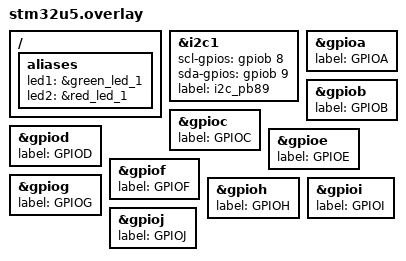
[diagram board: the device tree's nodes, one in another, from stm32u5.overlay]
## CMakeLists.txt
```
# SPDX-License-Identifier: Apache-2.0

cmake_minimum_required(VERSION 3.20.0)

set(DTC_OVERLAY_FILE stm32u5.overlay)
find_package(Zephyr REQUIRED HINTS $ENV{ZEPHYR_BASE})
project(shell_module)

target_sources(app PRIVATE src/main.c src/test_module.c src/misc_cmd.c)
target_sources_ifdef(CONFIG_SHELL_DYNAMIC_CMDS app PRIVATE src/dynamic_cmd.c)
target_sources_ifdef(CONFIG_SHELL_BACKEND_SERIAL app PRIVATE src/uart_reinit.c)
target_sources_ifdef(CONFIG_SHELL_START_OBSCURED app PRIVATE src/login_cmd.c)
```

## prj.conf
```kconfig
CONFIG_PRINTK=y
CONFIG_SHELL=y
CONFIG_LOG=y
CONFIG_LOG_CMDS=y
CONFIG_INIT_STACKS=y
CONFIG_THREAD_STACK_INFO=y
CONFIG_KERNEL_SHELL=y
CONFIG_THREAD_MONITOR=y
CONFIG_BOOT_BANNER=n
CONFIG_THREAD_NAME=y
CONFIG_DEVICE_SHELL=y
CONFIG_POSIX_API=y
CONFIG_POSIX_TIMERS=y
CONFIG_DATE_SHELL=y
CONFIG_THREAD_RUNTIME_STATS=y
CONFIG_THREAD_RUNTIME_STATS_USE_TIMING_FUNCTIONS=y
CONFIG_STATS=y
CONFIG_STATS_SHELL=y
CONFIG_GPIO=y
CONFIG_GPIO_SHELL=y
CONFIG_SHELL_DYNAMIC_CMDS=y
CONFIG_I2C=y
CONFIG_I2C_SHELL=y
CONFIG_FLASH=y
CONFIG_FLASH_SHELL=y
```

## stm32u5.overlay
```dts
/ {
	aliases {
		led1 = &green_led_1;
        led2 = &red_led_1;
	};
};

&i2c1 {
    status = "okay";
    scl-gpios = <&gpiob 8 GPIO_OPEN_DRAIN>; 
    sda-gpios = <&gpiob 9 GPIO_OPEN_DRAIN>; 
    label = "i2c_pb89";
};

&gpioa {
    label = "GPIOA";
};

&gpiob {
    label = "GPIOB";
};

&gpioc {
    label = "GPIOC";
};

&gpiod {
    label = "GPIOD";
};

&gpioe {
    label = "GPIOE";
};

&gpiof {
    label = "GPIOF";
};

&gpiog {
    label = "GPIOG";
};

&gpioh {
    label = "GPIOH";
};

&gpioi {
    label = "GPIOI";
};

&gpioj {
    label = "GPIOJ";
};
```

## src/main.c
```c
/*
 * Copyright (c) 2015 Intel Corporation
 *
 * SPDX-License-Identifier: Apache-2.0
 */

#include <zephyr/kernel.h>
#include <zephyr/shell/shell.h>
#include <zephyr/version.h>
#include <zephyr/logging/log.h>
#include <stdlib.h>
#include <zephyr/device.h>
#include <zephyr/drivers/uart.h>
#include <zephyr/usb/usb_device.h>
#include <zephyr/drivers/gpio.h>
#include <ctype.h>

#ifdef CONFIG_ARCH_POSIX
#include <unistd.h>
#else
#include <zephyr/posix/unistd.h>
#endif

/* The devicetree node identifier for the "led0" alias. */
#define LED0_NODE DT_ALIAS(led0)
#define LED1_NODE DT_ALIAS(led1)
#define LED2_NODE DT_ALIAS(led2)

LOG_MODULE_REGISTER(app);

struct led {
	struct gpio_dt_spec spec;
	uint8_t num;
};

static const struct led led0 = {
	.spec = GPIO_DT_SPEC_GET_OR(LED0_NODE, gpios, {0}),
	.num = 0,
};

static const struct led led1 = {
	.spec = GPIO_DT_SPEC_GET_OR(LED1_NODE, gpios, {0}),
	.num = 1,
};

void blink(const struct led *led, uint32_t sleep_ms, uint32_t id)
{
	const struct gpio_dt_spec *spec = &led->spec;
	int cnt = 0;
	int ret;

	if (!device_is_ready(spec->port)) {
		LOG_ERR("Error: %s device is not ready\n", spec->port->name);
		return;
	}

	ret = gpio_pin_configure_dt(spec, GPIO_OUTPUT);
	if (ret != 0) {
		LOG_ERR("Error %d: failed to configure pin %d (LED '%d')\n", ret, spec->pin,
			led->num);
		return;
	}

	while (1) {
		gpio_pin_set(spec->port, spec->pin, cnt % 2);

		k_msleep(sleep_ms);
		cnt++;
	}
}

void blink0_thread(void)
{
	blink(&led0, 1000, 0);
}

void blink1_thread(void)
{
	blink(&led1, 5000, 1);
}

#define LED_PRIORITY (6)
K_THREAD_DEFINE(blink0_id, 1024, blink0_thread, NULL, NULL, NULL, LED_PRIORITY, 0, 0);
K_THREAD_DEFINE(blink1_id, 1024, blink1_thread, NULL, NULL, NULL, LED_PRIORITY, 0, 0);
```

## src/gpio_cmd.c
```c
#include <zephyr/kernel.h>
#include <zephyr/shell/shell.h>
#include <zephyr/version.h>
#include <zephyr/logging/log.h>
#include <stdlib.h>
#include <zephyr/device.h>
#include <zephyr/drivers/uart.h>
#include <zephyr/usb/usb_device.h>
#include <zephyr/drivers/gpio.h>
#include <ctype.h>
#include <strings.h>

#ifdef CONFIG_ARCH_POSIX
#include <unistd.h>
#else
#include <zephyr/posix/unistd.h>
#endif

LOG_MODULE_REGISTER(app_gpio);

static const struct device *get_gpio_device_from_port(const char *port)
{
	if (strncasecmp(port, "A", 1) == 0) {
		return DEVICE_DT_GET(DT_NODELABEL(gpioa)); // GPIO Port A
	} else if (strncasecmp(port, "B", 1) == 0) {
		return DEVICE_DT_GET(DT_NODELABEL(gpiob)); // GPIO Port B
	} else if (strncasecmp(port, "C", 1) == 0) {
		return DEVICE_DT_GET(DT_NODELABEL(gpioc)); // GPIO Port C
	} else if (strncasecmp(port, "D", 1) == 0) {
		return DEVICE_DT_GET(DT_NODELABEL(gpiod)); // GPIO Port D
	} else if (strncasecmp(port, "E", 1) == 0) {
		return DEVICE_DT_GET(DT_NODELABEL(gpioe)); // GPIO Port E
	} else if (strncasecmp(port, "F", 1) == 0) {
		return DEVICE_DT_GET(DT_NODELABEL(gpiof)); // GPIO Port F
	} else if (strncasecmp(port, "G", 1) == 0) {
		return DEVICE_DT_GET(DT_NODELABEL(gpiog)); // GPIO Port G
	} else if (strncasecmp(port, "H", 1) == 0) {
		return DEVICE_DT_GET(DT_NODELABEL(gpioh)); // GPIO Port H
	} else if (strncasecmp(port, "I", 1) == 0) {
		return DEVICE_DT_GET(DT_NODELABEL(gpioi)); // GPIO Port I
	} else if (strncasecmp(port, "J", 1) == 0) {
		return DEVICE_DT_GET(DT_NODELABEL(gpioj)); // GPIO Port J
	}
	return NULL; // Invalid port
}
/* Command: Set GPIO Pin Direction (Input or Output) */
static int cmd_gpio_dir(const struct shell *shell, size_t argc, char **argv)
{
	if (argc != 4) {
		shell_print(shell, "Usage: gpio_dir <port> <pin> <input/output>");
		return -EINVAL;
	}

	const char *port = argv[1];
	int pin = atoi(argv[2]);
	const char *dir = argv[3];

	const struct device *gpio_dev = get_gpio_device_from_port(port);

	if (!gpio_dev) {
		shell_print(shell, "Invalid port: %s", port);
		return -EINVAL;
	}

	int ret;
	if (strcmp(dir, "input") == 0) {
		ret = gpio_pin_configure(gpio_dev, pin, GPIO_INPUT);
	} else if (strcmp(dir, "output") == 0) {
		ret = gpio_pin_configure(gpio_dev, pin, GPIO_OUTPUT);
	} else {
		shell_print(shell, "Invalid direction. Use 'input' or 'output'");
		return -EINVAL;
	}

	if (ret < 0) {
		shell_print(shell, "Failed to configure pin %d on port %s", pin, port);
		return ret;
	}

	shell_print(shell, "Port %s, Pin %d configured as %s", port, pin, dir);
	return 0;
}

/* Command: Set GPIO Pin State */
static int cmd_gpio_set(const struct shell *shell, size_t argc, char **argv)
{
	if (argc != 4) {
		shell_print(shell, "Usage: gpio_set <port> <pin> <0/1>");
		return -EINVAL;
	}

	const char *port = argv[1];
	int pin = atoi(argv[2]);
	int value = atoi(argv[3]);

	const struct device *gpio_dev = get_gpio_device_from_port(port);

	if (!gpio_dev) {
		shell_print(shell, "Invalid port: %s", port);
		return -EINVAL;
	}

	if (value != 0 && value != 1) {
		shell_print(shell, "Invalid value. Use 0 or 1.");
		return -EINVAL;
	}

	int ret = gpio_pin_set(gpio_dev, pin, value);
	if (ret < 0) {
		shell_print(shell, "Failed to set pin %d on port %s", pin, port);
		return ret;
	}

	shell_print(shell, "Port %s, Pin %d set to %d", port, pin, value);
	return 0;
}

/* Command: Get GPIO Pin State */
static int cmd_gpio_get(const struct shell *shell, size_t argc, char **argv)
{
	if (argc != 3) {
		shell_print(shell, "Usage: gpio_get <port> <pin>");
		return -EINVAL;
	}

	const char *port = argv[1];
	int pin = atoi(argv[2]);

	const struct device *gpio_dev = get_gpio_device_from_port(port);

	if (!gpio_dev) {
		shell_print(shell, "Invalid port: %s", port);
		return -EINVAL;
	}

	int value = gpio_pin_get(gpio_dev, pin);
	if (value < 0) {
		shell_print(shell, "Failed to get state of pin %d on port %s", pin, port);
		return value;
	}

	shell_print(shell, "Port %s, Pin %d is %d", port, pin, value);
	return 0;
}

/* GPIO Commands */
SHELL_STATIC_SUBCMD_SET_CREATE(sub_gpio,
			       SHELL_CMD(dir, NULL, "Set GPIO pin direction (input/output)",
					 cmd_gpio_dir),
			       SHELL_CMD(set, NULL, "Set GPIO pin value (0/1)", cmd_gpio_set),
			       SHELL_CMD(get, NULL, "Get GPIO pin value", cmd_gpio_get),
			       SHELL_SUBCMD_SET_END /* Asrray terminated. */
);
SHELL_CMD_REGISTER(gpio, &sub_gpio, "GPIO commands", NULL);
```

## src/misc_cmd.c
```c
#include <zephyr/kernel.h>
#include <zephyr/shell/shell.h>
#include <zephyr/version.h>
#include <zephyr/logging/log.h>
#include <stdlib.h>
#include <zephyr/device.h>
#include <zephyr/drivers/uart.h>
#include <zephyr/usb/usb_device.h>
#include <ctype.h>

#ifdef CONFIG_ARCH_POSIX
#include <unistd.h>
#else
#include <zephyr/posix/unistd.h>
#endif

LOG_MODULE_REGISTER(app_misc);

extern void foo(void);

void timer_expired_handler(struct k_timer *timer)
{
	LOG_INF("Timer expired.");

	/* Call another module to present logging from multiple sources. */
	foo();
}

K_TIMER_DEFINE(log_timer, timer_expired_handler, NULL);

static int cmd_log_test_start(const struct shell *sh, size_t argc, char **argv, uint32_t period)
{
	ARG_UNUSED(argv);

	k_timer_start(&log_timer, K_MSEC(period), K_MSEC(period));
	shell_print(sh, "Log test started\n");

	return 0;
}

static int cmd_log_test_start_demo(const struct shell *sh, size_t argc, char **argv)
{
	return cmd_log_test_start(sh, argc, argv, 200);
}

static int cmd_log_test_start_flood(const struct shell *sh, size_t argc, char **argv)
{
	return cmd_log_test_start(sh, argc, argv, 10);
}

static int cmd_log_test_stop(const struct shell *sh, size_t argc, char **argv)
{
	ARG_UNUSED(argc);
	ARG_UNUSED(argv);

	k_timer_stop(&log_timer);
	shell_print(sh, "Log test stopped");

	return 0;
}

SHELL_STATIC_SUBCMD_SET_CREATE(
	sub_log_test_start,
	SHELL_CMD_ARG(demo, NULL, "Start log timer which generates log message every 200ms.",
		      cmd_log_test_start_demo, 1, 0),
	SHELL_CMD_ARG(flood, NULL, "Start log timer which generates log message every 10ms.",
		      cmd_log_test_start_flood, 1, 0),
	SHELL_SUBCMD_SET_END /* Array terminated. */
);
SHELL_STATIC_SUBCMD_SET_CREATE(sub_log_test,
			       SHELL_CMD_ARG(start, &sub_log_test_start, "Start log test", NULL, 2,
					     0),
			       SHELL_CMD_ARG(stop, NULL, "Stop log test.", cmd_log_test_stop, 1, 0),
			       SHELL_SUBCMD_SET_END /* Array terminated. */
);

SHELL_CMD_REGISTER(log_test, &sub_log_test, "Log test", NULL);

static int cmd_demo_ping(const struct shell *sh, size_t argc, char **argv)
{
	ARG_UNUSED(argc);
	ARG_UNUSED(argv);

	shell_print(sh, "pong");

	return 0;
}

static int cmd_demo_board(const struct shell *sh, size_t argc, char **argv)
{
	ARG_UNUSED(argc);
	ARG_UNUSED(argv);

	shell_print(sh, CONFIG_BOARD);

	return 0;
}

#if defined CONFIG_SHELL_GETOPT
/* Thread save usage */
static int cmd_demo_getopt_ts(const struct shell *sh, size_t argc, char **argv)
{
	struct getopt_state *state;
	char *cvalue = NULL;
	int aflag = 0;
	int bflag = 0;
	int c;

	while ((c = getopt(argc, argv, "abhc:")) != -1) {
		state = getopt_state_get();
		switch (c) {
		case 'a':
			aflag = 1;
			break;
		case 'b':
			bflag = 1;
			break;
		case 'c':
			cvalue = state->optarg;
			break;
		case 'h':
			/* When getopt is active shell is not parsing
			 * command handler to print help message. It must
			 * be done explicitly.
			 */
			shell_help(sh);
			return SHELL_CMD_HELP_PRINTED;
		case '?':
			if (state->optopt == 'c') {
				shell_print(sh, "Option -%c requires an argument.", state->optopt);
			} else if (isprint(state->optopt) != 0) {
				shell_print(sh, "Unknown option `-%c'.", state->optopt);
			} else {
				shell_print(sh, "Unknown option character `\\x%x'.", state->optopt);
			}
			return 1;
		default:
			break;
		}
	}

	shell_print(sh, "aflag = %d, bflag = %d", aflag, bflag);
	return 0;
}

static int cmd_demo_getopt(const struct shell *sh, size_t argc, char **argv)
{
	char *cvalue = NULL;
	int aflag = 0;
	int bflag = 0;
	int c;

	while ((c = getopt(argc, argv, "abhc:")) != -1) {
		switch (c) {
		case 'a':
			aflag = 1;
			break;
		case 'b':
			bflag = 1;
			break;
		case 'c':
			cvalue = optarg;
			break;
		case 'h':
			/* When getopt is active shell is not parsing
			 * command handler to print help message. It must
			 * be done explicitly.
			 */
			shell_help(sh);
			return SHELL_CMD_HELP_PRINTED;
		case '?':
			if (optopt == 'c') {
				shell_print(sh, "Option -%c requires an argument.", optopt);
			} else if (isprint(optopt) != 0) {
				shell_print(sh, "Unknown option `-%c'.", optopt);
			} else {
				shell_print(sh, "Unknown option character `\\x%x'.", optopt);
			}
			return 1;
		default:
			break;
		}
	}

	shell_print(sh, "aflag = %d, bflag = %d", aflag, bflag);
	return 0;
}
#endif

static int cmd_demo_params(const struct shell *sh, size_t argc, char **argv)
{
	shell_print(sh, "argc = %zd", argc);
	for (size_t cnt = 0; cnt < argc; cnt++) {
		shell_print(sh, "  argv[%zd] = %s", cnt, argv[cnt]);
	}

	return 0;
}

static int cmd_demo_hexdump(const struct shell *sh, size_t argc, char **argv)
{
	shell_print(sh, "argc = %zd", argc);
	for (size_t cnt = 0; cnt < argc; cnt++) {
		shell_print(sh, "argv[%zd]", cnt);
		shell_hexdump(sh, argv[cnt], strlen(argv[cnt]));
	}

	return 0;
}

static int cmd_version(const struct shell *sh, size_t argc, char **argv)
{
	ARG_UNUSED(argc);
	ARG_UNUSED(argv);

	shell_print(sh, "Zephyr version %s", KERNEL_VERSION_STRING);

	return 0;
}

static int set_bypass(const struct shell *sh, shell_bypass_cb_t bypass)
{
	static bool in_use;

	if (bypass && in_use) {
		shell_error(sh, "Sample supports setting bypass on single instance.");

		return -EBUSY;
	}

	in_use = !in_use;
	if (in_use) {
		shell_print(sh, "Bypass started, press ctrl-x ctrl-q to escape");
		in_use = true;
	}

	shell_set_bypass(sh, bypass);

	return 0;
}

#define CHAR_1 0x18
#define CHAR_2 0x11

static void bypass_cb(const struct shell *sh, uint8_t *data, size_t len)
{
	static uint8_t tail;
	bool escape = false;

	/* Check if escape criteria is met. */
	if (tail == CHAR_1 && data[0] == CHAR_2) {
		escape = true;
	} else {
		for (int i = 0; i < (len - 1); i++) {
			if (data[i] == CHAR_1 && data[i + 1] == CHAR_2) {
				escape = true;
				break;
			}
		}
	}

	if (escape) {
		shell_print(sh, "Exit bypass");
		set_bypass(sh, NULL);
		tail = 0;
		return;
	}

	/* Store last byte for escape sequence detection */
	tail = data[len - 1];

	/* Do the data processing. */
	for (int i = 0; i < len; i++) {
		shell_fprintf(sh, SHELL_INFO, "%02x ", data[i]);
	}
	shell_fprintf(sh, SHELL_INFO, "| ");

	for (int i = 0; i < len; i++) {
		shell_fprintf(sh, SHELL_INFO, "%c", data[i]);
	}
	shell_fprintf(sh, SHELL_INFO, "\n");
}

static int cmd_bypass(const struct shell *sh, size_t argc, char **argv)
{
	return set_bypass(sh, bypass_cb);
}

static int cmd_dict(const struct shell *sh, size_t argc, char **argv, void *data)
{
	int val = (intptr_t)data;

	shell_print(sh, "(syntax, value) : (%s, %d)", argv[0], val);

	return 0;
}

SHELL_SUBCMD_DICT_SET_CREATE(sub_dict_cmds, cmd_dict, (value_0, 0, "value 0"),
			     (value_1, 1, "value 1"), (value_2, 2, "value 2"),
			     (value_3, 3, "value 3"));

SHELL_STATIC_SUBCMD_SET_CREATE(sub_demo,
			       SHELL_CMD(dictionary, &sub_dict_cmds, "Dictionary commands", NULL),
			       SHELL_CMD(hexdump, NULL, "Hexdump params command.",
					 cmd_demo_hexdump),
			       SHELL_CMD(params, NULL, "Print params command.", cmd_demo_params),
			       SHELL_CMD(ping, NULL, "Ping command.", cmd_demo_ping),
			       SHELL_CMD(board, NULL, "Show board name command.", cmd_demo_board),
#if defined CONFIG_SHELL_GETOPT
			       SHELL_CMD(getopt_thread_safe, NULL,
					 "Cammand using getopt in thread safe way"
					 " looking for: \"abhc:\".",
					 cmd_demo_getopt_ts),
			       SHELL_CMD(getopt, NULL,
					 "Cammand using getopt in non thread safe way"
					 " looking for: \"abhc:\".\n",
					 cmd_demo_getopt),
#endif
			       SHELL_SUBCMD_SET_END /* Array terminated. */
);
SHELL_CMD_REGISTER(demo, &sub_demo, "Demo commands", NULL);

SHELL_CMD_ARG_REGISTER(version, NULL, "Show kernel version", cmd_version, 1, 0);

SHELL_CMD_ARG_REGISTER(bypass, NULL, "Bypass shell", cmd_bypass, 1, 0);

/* Create a set of commands. Commands to this set are added using @ref SHELL_SUBCMD_ADD
 * and @ref SHELL_SUBCMD_COND_ADD.
 */
SHELL_SUBCMD_SET_CREATE(sub_section_cmd, (section_cmd));

static int cmd1_handler(const struct shell *sh, size_t argc, char **argv)
{
	ARG_UNUSED(sh);
	ARG_UNUSED(argc);
	ARG_UNUSED(argv);

	shell_print(sh, "cmd1 executed");

	return 0;
}

/* Create a set of subcommands for "section_cmd cm1". */
SHELL_SUBCMD_SET_CREATE(sub_section_cmd1, (section_cmd, cmd1));

/* Add command to the set. Subcommand set is identify by parent shell command. */
SHELL_SUBCMD_ADD((section_cmd), cmd1, &sub_section_cmd1, "help for cmd1", cmd1_handler, 1, 0);

SHELL_CMD_REGISTER(section_cmd, &sub_section_cmd,
		   "Demo command using section for subcommand registration", NULL);
```
